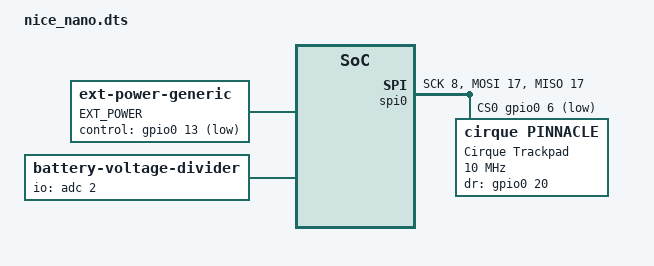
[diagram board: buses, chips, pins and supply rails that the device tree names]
/*
 * Copyright (c) 2021 The ZMK Contributors
 *
 * SPDX-License-Identifier: MIT
 */

/dts-v1/;
#include "nice_nano.dtsi"

/ {
	chosen {
		zmk,battery = &vbatt;
	};

	ext-power {
		compatible = "zmk,ext-power-generic";
		label = "EXT_POWER";
		control-gpios = <&gpio0 13 GPIO_ACTIVE_LOW>;
	};

	vbatt: vbatt {
		compatible = "zmk,battery-voltage-divider";
		label = "BATTERY";
		io-channels = <&adc 2>;
		output-ohms = <2000000>;
		full-ohms = <(2000000 + 806000)>;
	};
};


&spi0 {
    compatible = "nordic,nrf-spim";
    status = "okay";
    miso-pin = <17>; // P0.17
    mosi-pin = <17>; // should not be used 
    sck-pin = <8>; // P0.08
    cs-gpios = <&gpio0 6 GPIO_ACTIVE_LOW>; // P0.06

    trackpad@0 {
        compatible = "cirque,pinnacle";
        status = "okay";
        reg = <0>;
        label = "Cirque Trackpad";
        spi-max-frequency = <10000000>;
        dr-gpios = <&gpio0 20 GPIO_ACTIVE_HIGH>;
        invert-x;
        sleep;
        /* no-taps; */
    };
};
